# APM32F446 register map
File version: 1.0
CPU: CM4 r0p1, little endian, MPU, FPU, 4 interrupt priority bits
Registers are 32-bit, read-write, reset 0x0 unless marked. A register's access mark holds for its fields unless they carry their own. Offsets are from the block's base; [hi:lo] are bit positions; {n}, {i} and the like mark numbered series.

## LPUART0 — Low-power Universal asynchronous receiver/transmitters
Base 0x4006A000
Same registers: LPUART1 0x4006B000, LPUART2 0x4006C000
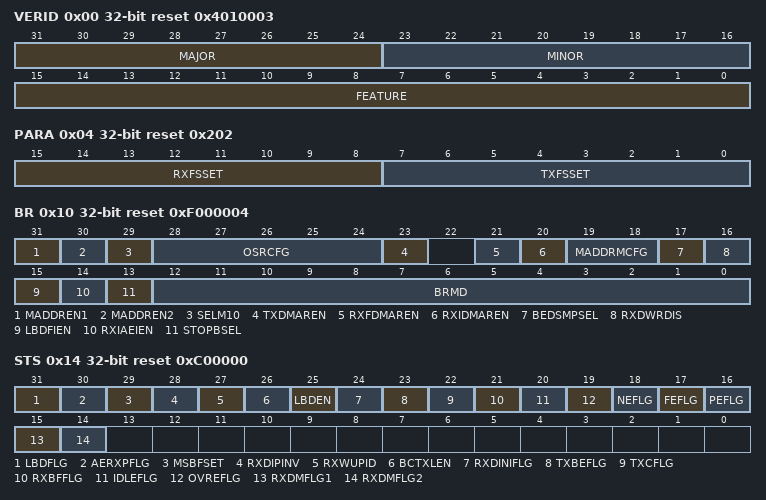
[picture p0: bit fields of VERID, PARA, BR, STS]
0x00 VERID ro reset 0x4010003 — Version ID Register
  [31:24] MAJOR — Major Version Number
  [23:16] MINOR — Minor Version Number
  [15:0] FEATURE — Feature Number
    1=Standard feature set; 3=Standard feature set with MODEM/IrDA support
0x04 PARA ro reset 0x202 — Parameter Register
  [15:8] RXFSSET — Receive FIFO Size Set
  [7:0] TXFSSET — Transmit FIFO Size Set
0x08 SWRST — LPUART Software Reset Register
  [1] SWRSTEN — Software Reset Enable
    0=Module is not reset; 1=Module is reset
0x0C PCFG — LPUART Pin Configuration Register
  [1:0] ITRGCFG — Input Trigger Configure
    0=Input trigger is disabled; 1=Input trigger is used instead of RXD pin input; 2=Input trigger is used instead of CTS_B pin input; 3=Input trigger is used to modulate the TXD pin output. The TXD pin output (after TXDOPINV configuration) is ANDed with the input trigger.
0x10 BR reset 0xF000004 — LPUART Baud Rate Register
  [31] MADDREN1 — Match Address 1 Mode Enable
    0=Normal operation; 1=Enables automatic address matching or data matching mode for MADDR[MADDR1]
  [30] MADDREN2 — Match Address 2 Mode Enable
    0=Normal operation; 1=Enables automatic address matching or data matching mode for MADDR[MADDR2]
  [29] SELM10 — 10-bit Mode Select
    0=Receiver and transmitter use 7-bit to 9-bit data characters; 1=Receiver and transmitter use 10-bit data characters
  [28:24] OSRCFG — Oversampling Ratio Configure
    0=Writing 0 to this field will result in an oversampling ratio of 16; {v}=Oversampling ratio of {v+1}, requires BEDSMPSEL to be set (v=3..6); {v}=Oversampling ratio of {v+1} (v=7..31)
  [23] TXDMAREN — Transmitter DMA Request Enable
    0=DMA request disabled; 1=DMA request enabled
  [21] RXFDMAREN — Receiver Full DMA Request Enable
    0=DMA request disabled; 1=DMA request enabled
  [20] RXIDMAREN — Receiver Idle DMA Request Enable
    0=DMA request disabled; 1=DMA request enabled
  [19:18] MADDRMCFG — Match Addressing Mode Configure
    0=Address Match Wakeup; 1=Idle Match Wakeup; 2=Match On and Match Off
  [17] BEDSMPSEL — Both Edge Sampling Mode Select
    0=Receiver samples input data using the rising edge of the baud rate clock; 1=Receiver samples input data using the rising and falling edge of the baud rate clock
  [16] RXDWRDIS — Received Data Word Resynchronization Disable
    0=Resynchronization during received data word is supported; 1=Resynchronization during received data word is disabled
  [15] LBDFIEN — LIN Break Detect Flag Interrupt Enable
    0=Hardware interrupts from LPUART_STS[LBDFLG] disabled (use polling); 1=Hardware interrupt requested when LPUART_STS[LBDFLG] flag is 1
  [14] RXIAEIEN — Receive Input Active Edge Interrupt Enable
    0=Hardware interrupts from LPUART_STS[AERXPFLG] disabled; 1=Hardware interrupt requested when LPUART_STS[AERXPFLG] flag is 1
  [13] STOPBSEL — Stop Bit Select
    0=One stop bit; 1=Two stop bits
  [12:0] BRMD — Baud Rate Modulo Divisor
0x14 STS reset 0xC00000 — LPUART Status Register
  [31] LBDFLG — LIN Break Detected Flag
    0=No LIN break character has been detected; 1=LIN break character has been detected
  [30] AERXPFLG — Active Edge on Receive Pin Flag
    0=No active edge on the receive pin has occurred; 1=An active edge on the receive pin has occurred
  [29] MSBFSET — MSB First Set
    0=LSB (bit0) is the first bit that is transmitted following the start bit. Further, the first bit received after the start bit is identified as bit0.; 1=MSB (bit9, bit8, bit7 or bit6) is the first bit that is transmitted following the start bit depending on the setting of CTRL[RXTXCSEL], CTRL[PECFG] and BR[SELM10]. Further, the first bit received after the start bit is identified as bit9, bit8, bit7 or bit6 depending on the setting of CTRL[RXTXCSEL] and CTRL[PECFG].
  [28] RXDIPINV — Received Data Input Polarity Inversion
    0=Receive data not inverted; 1=Receive data inverted
  [27] RXWUPID — Receive Wake Up Idle Detect
    0=During receive standby state (RXWUPCTRL = 1), the IDLE bit does not get set upon detection of an idle character. During address match wakeup, the IDLE bit does not set when an address does not match.; 1=During receive standby state (RXWUPCTRL = 1), the IDLE bit gets set upon detection of an idle character. During address match wakeup, the IDLE bit does set when an address does not match.
  [26] BCTXLEN — Break Character Transmission Length
    0=Break character is transmitted with length of 9 to 13 bit times; 1=Break character is transmitted with length of 12 to 15 bit times
  [25] LBDEN — LIN Break Detection Enable
    0=LIN break detect is disabled, normal break character can be detected; 1=LIN break detect is enabled. LIN break character is detected at length of 11 bit times (if RXTXCSEL = 0) or 12 (if RXTXCSEL = 1) or 13 (SELM10 = 1).
  [24] RXDINIFLG ro — RXD Input Not Idle Flag
    0=LPUART receiver idle waiting for a start bit; 1=LPUART receiver active (RXD input not idle)
  [23] TXBEFLG ro — Transmit Data Buffer Empty Flag
    0=Transmit data buffer full; 1=Transmit data buffer empty
  [22] TXCFLG ro — Transmission data Complete Flag
    0=Transmitter active (sending data, a preamble, or a break); 1=Transmitter idle (transmission activity complete)
  [21] RXBFFLG ro — Receive Data Buffer full Flag
    0=Receive data buffer empty; 1=Receive data buffer full
  [20] IDLEFLG — Idle Line Detected Flag
    0=No idle line detected; 1=Idle line was detected
  [19] OVREFLG — Overrun Error Flag
    0=No overrun; 1=Receive overrun (new LPUART data lost)
  [18] NEFLG — Noise Flag
    0=No noise detected; 1=Noise detected in the received character in LPUART_DATA
  [17] FEFLG — Fram Error Flag
    0=No framing error detected. This does not guarantee the framing is correct.; 1=Framing error
  [16] PEFLG — Parity Error Flag
    0=No parity error; 1=Parity error
  [15] RXDMFLG1 — Received Data Match 1 Flag
    0=Received data is not equal to MADDR1; 1=Received data is equal to MADDR1
  [14] RXDMFLG2 — Received Data Match 2 Flag
    0=Received data is not equal to MADDR2; 1=Received data is equal to MADDR2
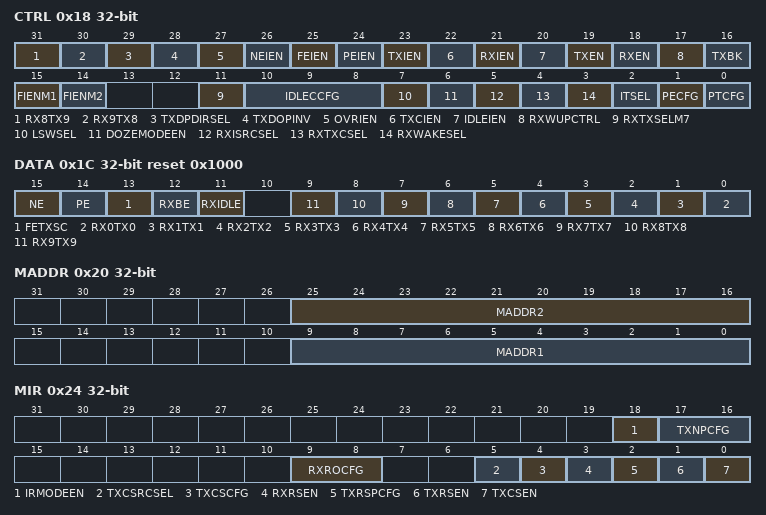
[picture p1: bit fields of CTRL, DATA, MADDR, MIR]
0x18 CTRL — LPUART Control Register
  [31] RX8TX9 — Receive Data Bit 8 / Transmit Data Bit 9
  [30] RX9TX8 — Receive Data Bit 9 / Transmit Data Bit 8
  [29] TXDPDIRSEL — TXD Pin Direction in Single-Wire Mode Select
    0=TXD pin is an input in single-wire mode; 1=TXD pin is an output in single-wire mode
  [28] TXDOPINV — Transmit Data Output Polarity Inversion
    0=Transmit data not inverted; 1=Transmit data inverted
  [27] OVRIEN — Overrun Interrupt Enable
    0=OVREFLG interrupts disabled; use polling; 1=Hardware interrupt requested when OVREFLG is set
  [26] NEIEN — Noise Error Interrupt Enable
    0=NEFLG interrupts disabled; use polling; 1=Hardware interrupt requested when NEFLG is set
  [25] FEIEN — Framing Error Interrupt Enable
    0=FEFLG interrupts disabled; use polling; 1=Hardware interrupt requested when FEFLG is set
  [24] PEIEN — Parity Error Interrupt Enable
    0=PEFLG interrupts disabled; use polling); 1=Hardware interrupt requested when PEFLG is set
  [23] TXIEN — Transmit Interrupt Enable
    0=Hardware interrupts from TXBEFLG disabled; use polling; 1=Hardware interrupt requested when TXBEFLG flag is 1
  [22] TXCIEN — Transmission Complete Interrupt Enable
    0=Hardware interrupts from TXCFLG disabled; use polling; 1=Hardware interrupt requested when TXCFLG flag is 1
  [21] RXIEN — Receiver Interrupt Enable
    0=Hardware interrupts from RXBFFLG disabled; use polling; 1=Hardware interrupt requested when RXBFFLG flag is 1
  [20] IDLEIEN — Idle Line Interrupt Enable
    0=Hardware interrupts from IDLE disabled; use polling; 1=Hardware interrupt requested when IDLE flag is 1
  [19] TXEN — LPUART Transmitter Enable
    0=Transmitter disabled; 1=Transmitter enabled
  [18] RXEN — LPUART Receiver Enable
    0=Receiver disabled; 1=Receiver enabled
  [17] RXWUPCTRL — Receiver Wakeup Control
    0=Normal receiver operation; 1=LPUART receiver in standby waiting for wakeup condition
  [16] TXBK — Transmit Break
    0=Normal transmitter operation; 1=Queue break character(s) to be sent
  [15] FIENM1 — Match 1 Flag Interrupt Enable
    0=RXDMFLG1 interrupt disabled; 1=RXDMFLG1 interrupt enabled
  [14] FIENM2 — Match 2 Flag Interrupt Enable
    0=RXDMFLG2 interrupt disabled; 1=RXDMFLG2 interrupt enabled
  [11] RXTXSELM7 — Receiver and Transmit Select 7-bit Mode
    0=Receiver and transmitter use 8-bit to 10-bit data characters; 1=Receiver and transmitter use 7-bit data characters
  [10:8] IDLECCFG — Idle Character Configure
    0=1 idle character; 1=2 idle characters; 2=4 idle characters; 3=8 idle characters; 4=16 idle characters; 5=32 idle characters; 6=64 idle characters; 7=128 idle characters
  [7] LSWSEL — Loop Mode or Single-wire Mode Select
    0=Normal operation - RXD and TXD use separate pins; 1=Loop mode or single-wire mode where transmitter outputs are internally connected to receiver input (see RXISRCSEL bit)
  [6] DOZEMODEEN — Doze Mode Enable
    0=LPUART is enabled in Doze mode; 1=LPUART is disabled in Doze mode
  [5] RXISRCSEL — Receiver Input Source Select
    0=Provided LSWSEL is set, RXISRCSEL is cleared, selects internal loop back mode and the LPUART does not use the RXD pin; 1=Single-wire LPUART mode where the TXD pin is connected to the transmitter output and receiver input
  [4] RXTXCSEL — Receiver and Transmit Character Select
    0=Receiver and transmitter use 8-bit data characters; 1=Receiver and transmitter use 9-bit data characters
  [3] RXWAKESEL — Receiver Wakeup Method Select
    0=Configures RXWUPCTRL for idle-line wakeup; 1=Configures RXWUPCTRL with address-mark wakeup
  [2] ITSEL — Idle Type Select
    0=Idle character bit count starts after start bit; 1=Idle character bit count starts after stop bit
  [1] PECFG — Parity Enable Configure
    0=No hardware parity generation or checking; 1=Parity enabled
  [0] PTCFG — Parity Type Configure
    0=Even parity; 1=Odd parity
0x1C DATA reset 0x1000 — LPUART Data Register
  [15] NE ro — Noise Error
    0=The dataword was received without noise; 1=The data was received with noise
  [14] PE ro — Parity Error
    0=The dataword was received without a parity error; 1=The dataword was received with a parity error
  [13] FETXSC — Frame Error or Transmit Special Character
    0=The dataword was received without a frame error on read, or transmit a normal character on write; 1=The dataword was received with a frame error, or transmit an idle or break character on transmit
  [12] RXBE ro — Receive Buffer Empty
    0=Receive buffer contains valid data; 1=Receive buffer is empty, data returned on read is not valid
  [11] RXIDLE ro — Receiver Idle Line
    0=Receiver was not idle before receiving this character; 1=Receiver was idle before receiving this character
  [n] RX{n}TX{n} (n=0..9) — Rx Buffer {n} or Tx Buffer {n}
0x20 MADDR — LPUART Match Address Register
  [25:16] MADDR2 — Match Address 2
  [9:0] MADDR1 — Match Address 1
0x24 MIR — LPUART Modem IrDA Register
  [18] IRMODEEN — Infrared Modulation/Demodulation Enable
    0=IR disabled; 1=IR enabled
  [17:16] TXNPCFG — Transmitter Narrow Pulse Configure
    {v}={v+1}/OSR (v=0..3)
  [9:8] RXROCFG — Receive RTS Output Configure
  [5] TXCSRCSEL — Transmit CTS Source Select
    0=CTS input is the CTS_B pin; 1=CTS input is the inverted Receiver Match result
  [4] TXCSCFG — Transmit CTS Sample Configure
    0=CTS input is sampled at the start of each character; 1=CTS input is sampled when the transmitter is idle
  [3] RXRSEN — Receiver Request-to-Send Enable
    0=The receiver has no effect on RTS
  [2] TXRSPCFG — Transmitter Request-to-Send Polarity Configure
    0=Transmitter RTS is active low; 1=Transmitter RTS is active high
  [1] TXRSEN — Transmitter Request-to-Send Enable
    0=The transmitter has no effect on RTS; 1=When a character is placed into an empty transmitter data buffer , RTS asserts one bit time before the start bit is transmitted. RTS deasserts one bit time after all characters in the transmitter data buffer and shift register are completely sent, including the last stop bit.
  [0] TXCSEN — Transmitter Clear-to-Send Enable
    0=CTS has no effect on the transmitter; 1=Enables clear-to-send operation. The transmitter checks the state of CTS each time it is ready to send a character. If CTS is asserted, the character is sent. If CTS is deasserted, the signal TXD remains in the mark state and transmission is delayed until CTS is asserted. Changes in CTS as a character is being sent do not affect its transmission.
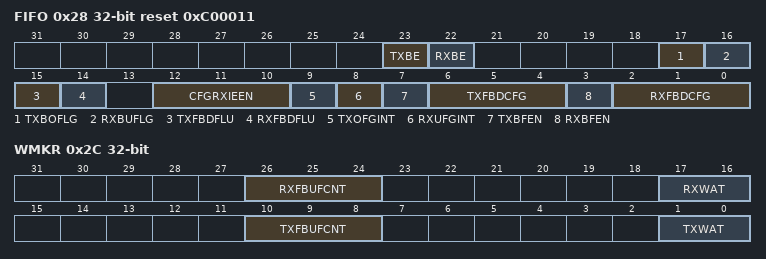
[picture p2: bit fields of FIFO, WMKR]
0x28 FIFO reset 0xC00011 — LPUART FIFO Register
  [23] TXBE ro — Transmit Buffer Empty
    0=Transmit buffer is not empty; 1=Transmit buffer is empty
  [22] RXBE ro — Receive Buffer Empty
    0=Receive buffer is not empty; 1=Receive buffer is empty
  [17] TXBOFLG — Transmitter Buffer Overflow Occured Flag
    0=No transmit buffer overflow has occurred since the last time the flag was cleared; 1=At least one transmit buffer overflow has occurred since the last time the flag was cleared
  [16] RXBUFLG — Receiver Buffer Underflow Occured Flag
    0=No receive buffer underflow has occurred since the last time the flag was cleared; 1=At least one receive buffer underflow has occurred since the last time the flag was cleared
  [15] TXFBDFLU wo — Transmit FIFO/Buffer Data Flush
    0=No flush operation occurs; 1=All data in the transmit FIFO/Buffer is cleared out
  [14] RXFBDFLU wo — Receive FIFO/Buffer Data Flush
    0=No flush operation occurs; 1=All data in the receive FIFO/buffer is cleared out
  [12:10] CFGRXIEEN — Configures when the Receiver is Idle Empty Enable
    0=Disable RXBFFLG assertion due to partially filled FIFO when receiver is idle; 1=Enable RXBFFLG assertion due to partially filled FIFO when receiver is idle for 1 character; 2=Enable RXBFFLG assertion due to partially filled FIFO when receiver is idle for 2 characters; 3=Enable RXBFFLG assertion due to partially filled FIFO when receiver is idle for 4 characters; 4=Enable RXBFFLG assertion due to partially filled FIFO when receiver is idle for 8 characters; 5=Enable RXBFFLG assertion due to partially filled FIFO when receiver is idle for 16 characters; 6=Enable RXBFFLG assertion due to partially filled FIFO when receiver is idle for 32 characters; 7=Enable RXBFFLG assertion due to partially filled FIFO when receiver is idle for 64 characters
  [9] TXOFGINT — TX Buffer Overflow Flag Generate Interrupt
    0=TXBOFLG flag does not generate an interrupt to the host; 1=TXBOFLG flag generates an interrupt to the host
  [8] RXUFGINT — RX Buffer Underflow Flag Generate Interrupt
    0=RXBUFLG flag does not generate an interrupt to the host; 1=RXBUFLG flag generates an interrupt to the host
  [7] TXBFEN — Transmit Buffer FIFO Enable
    0=Transmit FIFO is not enabled. Buffer is depth 1. (Legacy support).; 1=Transmit FIFO is enabled. Buffer is depth indicated by TXFIFOSIZE.
  [6:4] TXFBDCFG ro — Transmit FIFO Buffer Depth Configure
    0=Transmit FIFO/Buffer depth = 1 dataword; 1=Transmit FIFO/Buffer depth = 4 datawords; 2=Transmit FIFO/Buffer depth = 8 datawords; 3=Transmit FIFO/Buffer depth = 16 datawords; 4=Transmit FIFO/Buffer depth = 32 datawords; 5=Transmit FIFO/Buffer depth = 64 datawords; 6=Transmit FIFO/Buffer depth = 128 datawords; 7=Transmit FIFO/Buffer depth = 256 datawords
  [3] RXBFEN — Receive Buffer FIFO Enable
    0=Receive FIFO is not enabled. Buffer is depth 1. (Legacy support); 1=Receive FIFO is enabled. Buffer is depth indicted by RXFIFOSIZE.
  [2:0] RXFBDCFG ro — Receive FIFO Buffer Depth Configure
    0=Receive FIFO/Buffer depth = 1 dataword; 1=Receive FIFO/Buffer depth = 4 datawords; 2=Receive FIFO/Buffer depth = 8 datawords; 3=Receive FIFO/Buffer depth = 16 datawords; 4=Receive FIFO/Buffer depth = 32 datawords; 5=Receive FIFO/Buffer depth = 64 datawords; 6=Receive FIFO/Buffer depth = 128 datawords; 7=Receive FIFO/Buffer depth = 256 datawords
0x2C WMKR — LPUART Watermark Register
  [26:24] RXFBUFCNT ro — Receive FIFO/Buffer Counter
  [17:16] RXWAT — Receive Watermark
  [10:8] TXFBUFCNT ro — Transmit FIFO/Buffer Counter
  [1:0] TXWAT — Transmit Watermark
